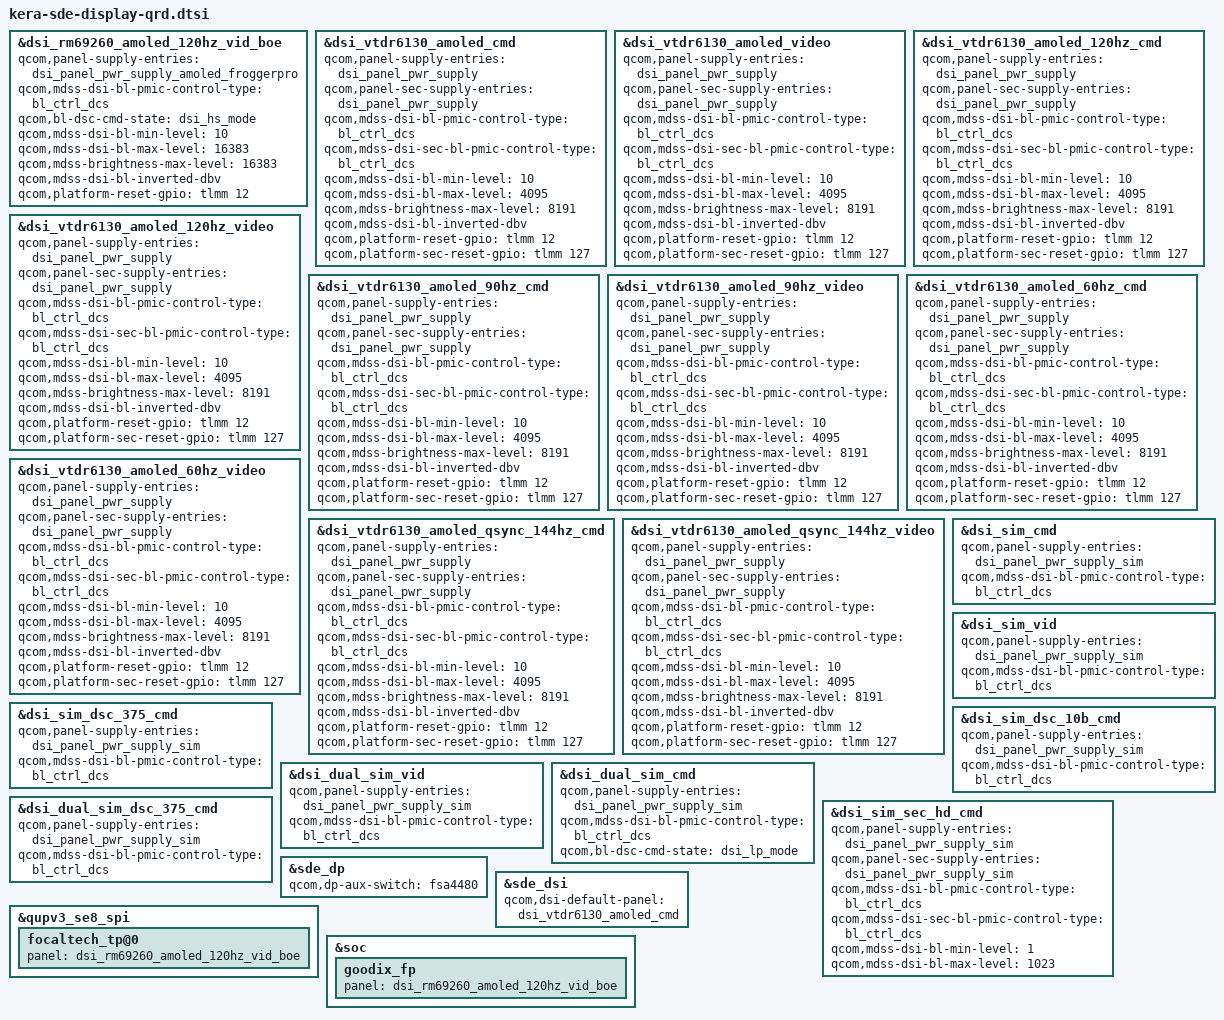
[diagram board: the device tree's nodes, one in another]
// SPDX-License-Identifier: BSD-3-Clause
/*
 * Copyright (c) 2024-2025 Qualcomm Innovation Center, Inc. All rights reserved.
 */

#include "kera-sde-display.dtsi"

&dsi_rm69260_amoled_120hz_vid_boe {
	qcom,panel-supply-entries = <&dsi_panel_pwr_supply_amoled_froggerpro>;
	qcom,mdss-dsi-bl-pmic-control-type = "bl_ctrl_dcs";
	qcom,bl-dsc-cmd-state = "dsi_hs_mode";
	qcom,mdss-dsi-bl-min-level = <10>;
	qcom,mdss-dsi-bl-max-level = <16383>;
	qcom,mdss-brightness-max-level = <16383>;
	qcom,mdss-dsi-bl-inverted-dbv;
	qcom,platform-reset-gpio = <&tlmm 12 0>;
};

&dsi_vtdr6130_amoled_cmd {
	qcom,panel-supply-entries = <&dsi_panel_pwr_supply>;
	qcom,panel-sec-supply-entries = <&dsi_panel_pwr_supply>;
	qcom,mdss-dsi-bl-pmic-control-type = "bl_ctrl_dcs";
	qcom,mdss-dsi-sec-bl-pmic-control-type = "bl_ctrl_dcs";
	qcom,mdss-dsi-bl-min-level = <10>;
	qcom,mdss-dsi-bl-max-level = <4095>;
	qcom,mdss-brightness-max-level = <8191>;
	qcom,mdss-dsi-bl-inverted-dbv;
	qcom,platform-reset-gpio = <&tlmm 12 0>;
	qcom,platform-sec-reset-gpio = <&tlmm 127 0>;
};

&dsi_vtdr6130_amoled_video {
	qcom,panel-supply-entries = <&dsi_panel_pwr_supply>;
	qcom,panel-sec-supply-entries = <&dsi_panel_pwr_supply>;
	qcom,mdss-dsi-bl-pmic-control-type = "bl_ctrl_dcs";
	qcom,mdss-dsi-sec-bl-pmic-control-type = "bl_ctrl_dcs";
	qcom,mdss-dsi-bl-min-level = <10>;
	qcom,mdss-dsi-bl-max-level = <4095>;
	qcom,mdss-brightness-max-level = <8191>;
	qcom,mdss-dsi-bl-inverted-dbv;
	qcom,platform-reset-gpio = <&tlmm 12 0>;
	qcom,platform-sec-reset-gpio = <&tlmm 127 0>;
};

&dsi_vtdr6130_amoled_120hz_cmd {
	qcom,panel-supply-entries = <&dsi_panel_pwr_supply>;
	qcom,panel-sec-supply-entries = <&dsi_panel_pwr_supply>;
	qcom,mdss-dsi-bl-pmic-control-type = "bl_ctrl_dcs";
	qcom,mdss-dsi-sec-bl-pmic-control-type = "bl_ctrl_dcs";
	qcom,mdss-dsi-bl-min-level = <10>;
	qcom,mdss-dsi-bl-max-level = <4095>;
	qcom,mdss-brightness-max-level = <8191>;
	qcom,mdss-dsi-bl-inverted-dbv;
	qcom,platform-reset-gpio = <&tlmm 12 0>;
	qcom,platform-sec-reset-gpio = <&tlmm 127 0>;
};

&dsi_vtdr6130_amoled_120hz_video {
	qcom,panel-supply-entries = <&dsi_panel_pwr_supply>;
	qcom,panel-sec-supply-entries = <&dsi_panel_pwr_supply>;
	qcom,mdss-dsi-bl-pmic-control-type = "bl_ctrl_dcs";
	qcom,mdss-dsi-sec-bl-pmic-control-type = "bl_ctrl_dcs";
	qcom,mdss-dsi-bl-min-level = <10>;
	qcom,mdss-dsi-bl-max-level = <4095>;
	qcom,mdss-brightness-max-level = <8191>;
	qcom,mdss-dsi-bl-inverted-dbv;
	qcom,platform-reset-gpio = <&tlmm 12 0>;
	qcom,platform-sec-reset-gpio = <&tlmm 127 0>;
};

&dsi_vtdr6130_amoled_90hz_cmd {
	qcom,panel-supply-entries = <&dsi_panel_pwr_supply>;
	qcom,panel-sec-supply-entries = <&dsi_panel_pwr_supply>;
	qcom,mdss-dsi-bl-pmic-control-type = "bl_ctrl_dcs";
	qcom,mdss-dsi-sec-bl-pmic-control-type = "bl_ctrl_dcs";
	qcom,mdss-dsi-bl-min-level = <10>;
	qcom,mdss-dsi-bl-max-level = <4095>;
	qcom,mdss-brightness-max-level = <8191>;
	qcom,mdss-dsi-bl-inverted-dbv;
	qcom,platform-reset-gpio = <&tlmm 12 0>;
	qcom,platform-sec-reset-gpio = <&tlmm 127 0>;
};

&dsi_vtdr6130_amoled_90hz_video {
	qcom,panel-supply-entries = <&dsi_panel_pwr_supply>;
	qcom,panel-sec-supply-entries = <&dsi_panel_pwr_supply>;
	qcom,mdss-dsi-bl-pmic-control-type = "bl_ctrl_dcs";
	qcom,mdss-dsi-sec-bl-pmic-control-type = "bl_ctrl_dcs";
	qcom,mdss-dsi-bl-min-level = <10>;
	qcom,mdss-dsi-bl-max-level = <4095>;
	qcom,mdss-brightness-max-level = <8191>;
	qcom,mdss-dsi-bl-inverted-dbv;
	qcom,platform-reset-gpio = <&tlmm 12 0>;
	qcom,platform-sec-reset-gpio = <&tlmm 127 0>;
};

&dsi_vtdr6130_amoled_60hz_cmd {
	qcom,panel-supply-entries = <&dsi_panel_pwr_supply>;
	qcom,panel-sec-supply-entries = <&dsi_panel_pwr_supply>;
	qcom,mdss-dsi-bl-pmic-control-type = "bl_ctrl_dcs";
	qcom,mdss-dsi-sec-bl-pmic-control-type = "bl_ctrl_dcs";
	qcom,mdss-dsi-bl-min-level = <10>;
	qcom,mdss-dsi-bl-max-level = <4095>;
	qcom,mdss-brightness-max-level = <8191>;
	qcom,mdss-dsi-bl-inverted-dbv;
	qcom,platform-reset-gpio = <&tlmm 12 0>;
	qcom,platform-sec-reset-gpio = <&tlmm 127 0>;
};

&dsi_vtdr6130_amoled_60hz_video {
	qcom,panel-supply-entries = <&dsi_panel_pwr_supply>;
	qcom,panel-sec-supply-entries = <&dsi_panel_pwr_supply>;
	qcom,mdss-dsi-bl-pmic-control-type = "bl_ctrl_dcs";
	qcom,mdss-dsi-sec-bl-pmic-control-type = "bl_ctrl_dcs";
	qcom,mdss-dsi-bl-min-level = <10>;
	qcom,mdss-dsi-bl-max-level = <4095>;
	qcom,mdss-brightness-max-level = <8191>;
	qcom,mdss-dsi-bl-inverted-dbv;
	qcom,platform-reset-gpio = <&tlmm 12 0>;
	qcom,platform-sec-reset-gpio = <&tlmm 127 0>;
};

&dsi_vtdr6130_amoled_qsync_144hz_cmd {
	qcom,panel-supply-entries = <&dsi_panel_pwr_supply>;
	qcom,panel-sec-supply-entries = <&dsi_panel_pwr_supply>;
	qcom,mdss-dsi-bl-pmic-control-type = "bl_ctrl_dcs";
	qcom,mdss-dsi-sec-bl-pmic-control-type = "bl_ctrl_dcs";
	qcom,mdss-dsi-bl-min-level = <10>;
	qcom,mdss-dsi-bl-max-level = <4095>;
	qcom,mdss-brightness-max-level = <8191>;
	qcom,mdss-dsi-bl-inverted-dbv;
	qcom,platform-reset-gpio = <&tlmm 12 0>;
	qcom,platform-sec-reset-gpio = <&tlmm 127 0>;
};

&dsi_vtdr6130_amoled_qsync_144hz_video {
	qcom,panel-supply-entries = <&dsi_panel_pwr_supply>;
	qcom,panel-sec-supply-entries = <&dsi_panel_pwr_supply>;
	qcom,mdss-dsi-bl-pmic-control-type = "bl_ctrl_dcs";
	qcom,mdss-dsi-sec-bl-pmic-control-type = "bl_ctrl_dcs";
	qcom,mdss-dsi-bl-min-level = <10>;
	qcom,mdss-dsi-bl-max-level = <4095>;
	qcom,mdss-brightness-max-level = <8191>;
	qcom,mdss-dsi-bl-inverted-dbv;
	qcom,platform-reset-gpio = <&tlmm 12 0>;
	qcom,platform-sec-reset-gpio = <&tlmm 127 0>;
};

&dsi_sim_cmd {
	qcom,panel-supply-entries = <&dsi_panel_pwr_supply_sim>;
	qcom,mdss-dsi-bl-pmic-control-type = "bl_ctrl_dcs";
};

&dsi_sim_vid {
	qcom,panel-supply-entries = <&dsi_panel_pwr_supply_sim>;
	qcom,mdss-dsi-bl-pmic-control-type = "bl_ctrl_dcs";
};

&dsi_sim_dsc_375_cmd {
	qcom,panel-supply-entries = <&dsi_panel_pwr_supply_sim>;
	qcom,mdss-dsi-bl-pmic-control-type = "bl_ctrl_dcs";
};

&dsi_sim_dsc_10b_cmd {
	qcom,panel-supply-entries = <&dsi_panel_pwr_supply_sim>;
	qcom,mdss-dsi-bl-pmic-control-type = "bl_ctrl_dcs";
};

&dsi_dual_sim_vid {
	qcom,panel-supply-entries = <&dsi_panel_pwr_supply_sim>;
	qcom,mdss-dsi-bl-pmic-control-type = "bl_ctrl_dcs";
};

&dsi_dual_sim_cmd {
	qcom,panel-supply-entries = <&dsi_panel_pwr_supply_sim>;
	qcom,mdss-dsi-bl-pmic-control-type = "bl_ctrl_dcs";
	qcom,bl-dsc-cmd-state = "dsi_lp_mode";
};

&dsi_dual_sim_dsc_375_cmd {
	qcom,panel-supply-entries = <&dsi_panel_pwr_supply_sim>;
	qcom,mdss-dsi-bl-pmic-control-type = "bl_ctrl_dcs";
};

&dsi_sim_sec_hd_cmd {
	qcom,panel-supply-entries = <&dsi_panel_pwr_supply_sim>;
	qcom,panel-sec-supply-entries = <&dsi_panel_pwr_supply_sim>;
	qcom,mdss-dsi-bl-pmic-control-type = "bl_ctrl_dcs";
	qcom,mdss-dsi-sec-bl-pmic-control-type = "bl_ctrl_dcs";
	qcom,mdss-dsi-bl-min-level = <1>;
	qcom,mdss-dsi-bl-max-level = <1023>;
};

&sde_dp {
	qcom,dp-aux-switch = <&fsa4480>;
};

&sde_dsi {
	qcom,dsi-default-panel = <&dsi_vtdr6130_amoled_cmd>;
};

&qupv3_se8_spi {
	focaltech_tp@0 {
		panel = <&dsi_rm69260_amoled_120hz_vid_boe>;
	};
};

&soc {
	goodix_fp {
		panel = <&dsi_rm69260_amoled_120hz_vid_boe>;
	};
};
